AUTOSAR XML (schema 4-0-3)
standard types defined: UInt32
package /PATAC/MSM/ComponentTypes
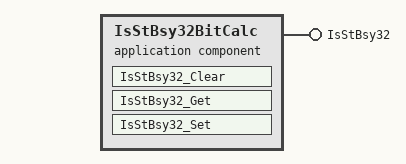
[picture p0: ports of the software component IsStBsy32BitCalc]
  application sw component type IsStBsy32BitCalc
    provide port IsStBsy32: provided-com-specs=[{operation=Clear, queue-length=1}, {operation=Get, queue-length=1}, {operation=Set, queue-length=1}], provided-interface=IsStBsy32
    behavior IsStBsy32BitCalc_InternalBehavior
      operation invoked event OIT_IsStBsy32_Clear_IsStBsy32_Clear: start-on-event=IsStBsy32_Clear, operation=IsStBsy32.Clear
      operation invoked event OIT_IsStBsy32_Get_IsStBsy32_Get: start-on-event=IsStBsy32_Get, operation=IsStBsy32.Get
      operation invoked event OIT_IsStBsy32_Set_IsStBsy32_Set: start-on-event=IsStBsy32_Set, operation=IsStBsy32.Set
      runnable IsStBsy32_Clear
      runnable IsStBsy32_Get
      runnable IsStBsy32_Set
  swc implementation IsStBsy32BitCalc_Implementation: behavior=IsStBsy32BitCalc_InternalBehavior
    code-descriptors:
      code Default: artifact-descriptors=autosar-engineering-object={short-label=Default, category=SWSRC}
package /PATAC/MSM/ModeAdjust/PortInterface
  client server interface IsStBsy32
    operation Clear
      arg ClearBit: type=UInt32, direction=IN, server-argument-impl-policy=USE-ARGUMENT-TYPE
    operation Get
      arg IsStBsy32Bit: type=UInt32, direction=OUT, server-argument-impl-policy=USE-ARGUMENT-TYPE
    operation Set
      arg SetBit: type=UInt32, direction=IN, server-argument-impl-policy=USE-ARGUMENT-TYPE
